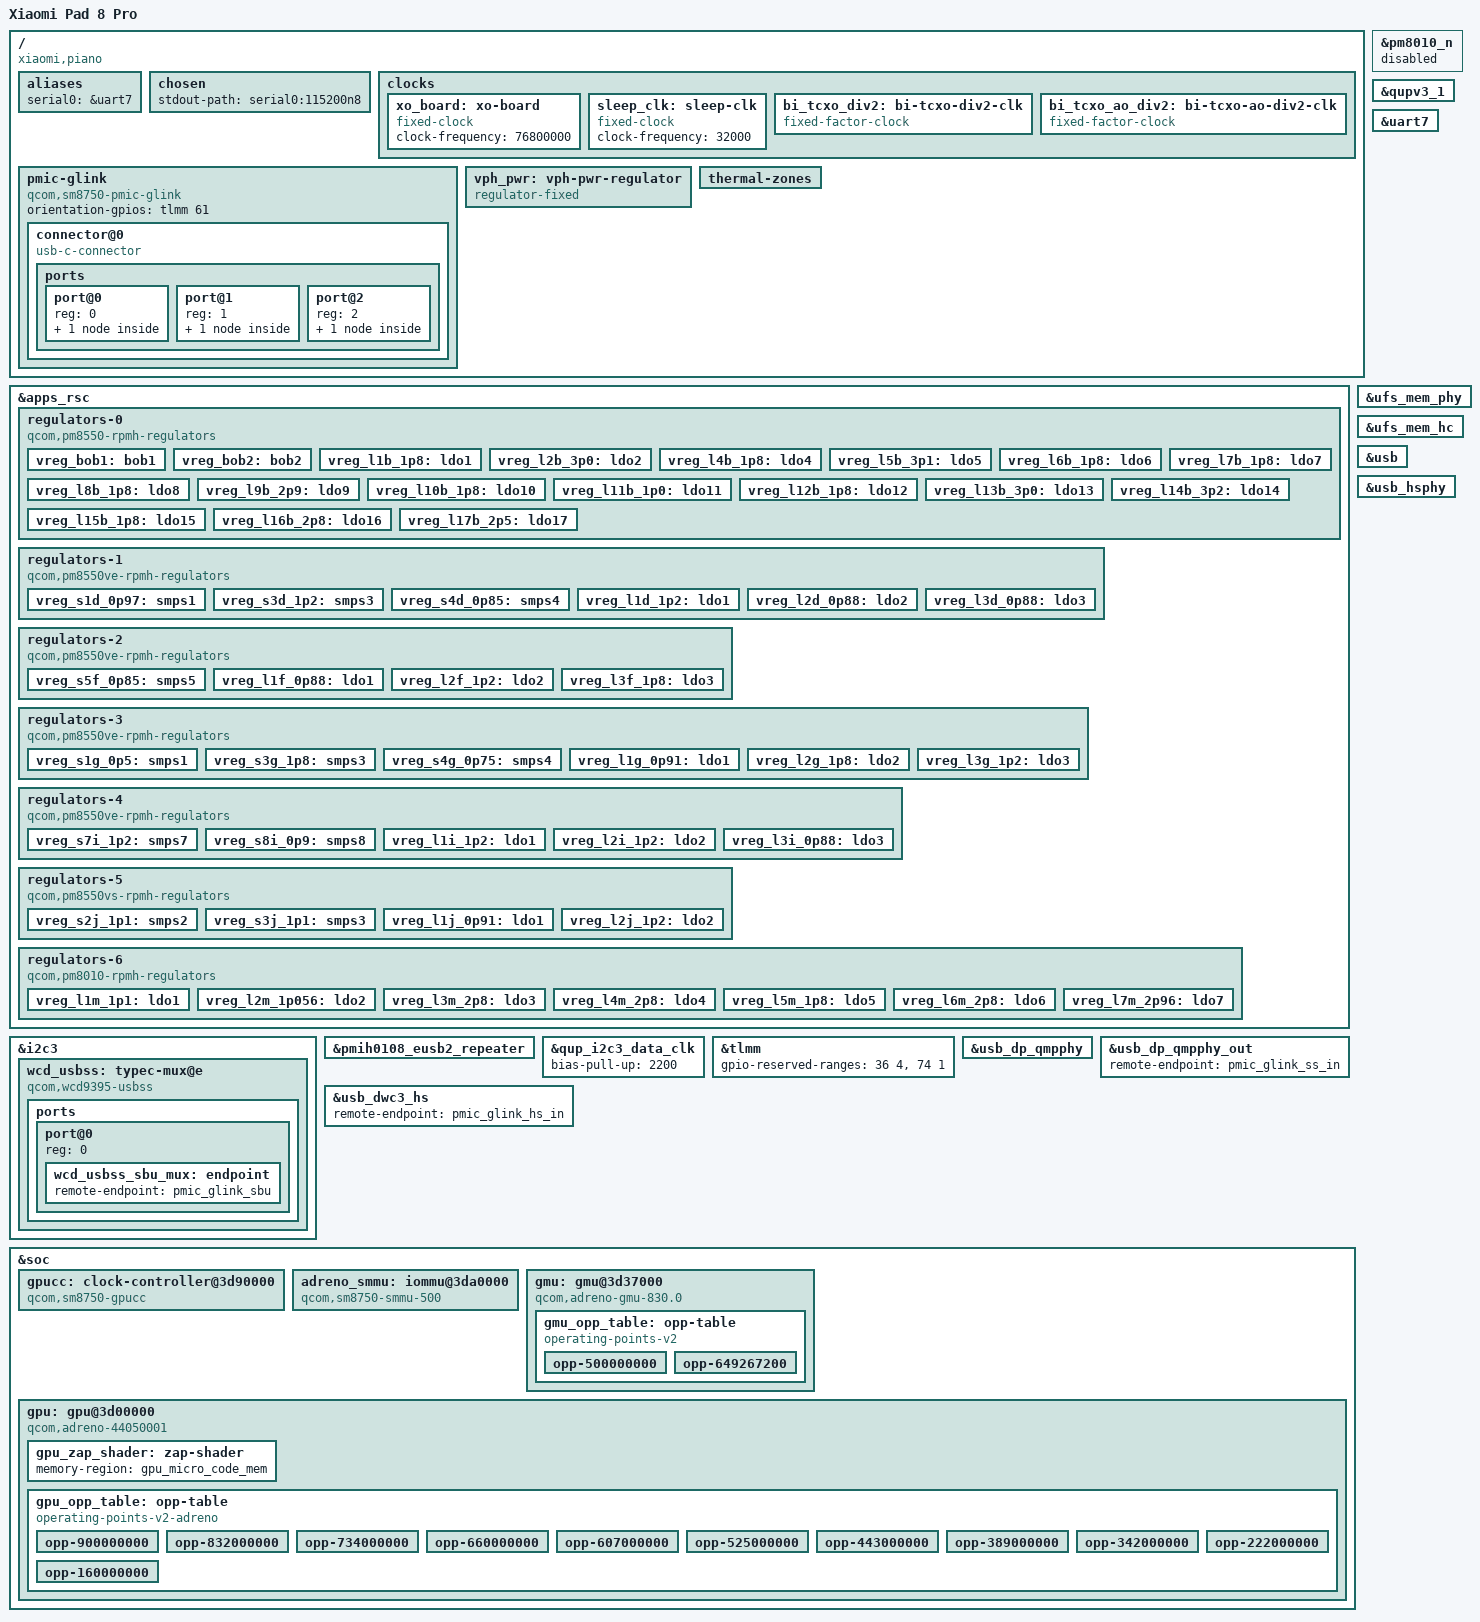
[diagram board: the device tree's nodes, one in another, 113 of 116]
// SPDX-License-Identifier: BSD-3-Clause
/*
 * Copyright (c) 2026, Xiaomi Pad 8 Pro (piano) mainline contributors
 *
 * Xiaomi Pad 8 Pro (codename "piano") bring-up skeleton, structured after
 * the in-tree SM8750 MTP board device tree.
 *
 * v0 scope: first-boot links only — UART7 console, UFS storage, USB DWC3
 * with the eUSB2/QMP PHY stack and the pmic-glink-managed USB-C connector.
 * Display/DSI, audio, WLAN/BT, PCIe, SD, LEDs, touch, keyboard, sensors,
 * GPU and all remoteproc firmware users are intentionally not enabled
 * until they are validated on real hardware.
 *
 * Value provenance markers:
 *   (M) value carried over from the in-tree SM8750 MTP board file
 *   (R) value cross-checked against the Xiaomi downstream kernel
 *       (refer/MiCode_piano/kernel_devicetree)
 * Open questions refer to docs/hardware-facts.md in the umbrella repo.
 */

/dts-v1/;

#include <dt-bindings/gpio/gpio.h>
#include <dt-bindings/regulator/qcom,rpmh-regulator.h>
#include <dt-bindings/clock/qcom,sm8750-gpucc.h>
#include "sm8750.dtsi"
#include "pm8010.dtsi"
#include "pm8550.dtsi"
#define PMK8550VE_SID 8
#include "pm8550ve.dtsi"
#include "pmd8028.dtsi"
#include "pmih0108.dtsi"
#include "pmk8550.dtsi"
#include "pmr735d_a.dtsi"
#include "sm8750-pmics.dtsi"

/ {
	model = "Xiaomi Pad 8 Pro";
	compatible = "xiaomi,piano", "qcom,sm8750";
	chassis-type = "tablet";

	aliases {
		serial0 = &uart7;
	};

	chosen {
		stdout-path = "serial0:115200n8";
	};

	clocks {
		xo_board: xo-board {
			compatible = "fixed-clock";
			clock-frequency = <76800000>;		/* (M) */
			#clock-cells = <0>;
		};

		sleep_clk: sleep-clk {
			compatible = "fixed-clock";
			clock-frequency = <32000>;		/* (M) */
			#clock-cells = <0>;
		};

		bi_tcxo_div2: bi-tcxo-div2-clk {
			compatible = "fixed-factor-clock";
			#clock-cells = <0>;

			clocks = <&rpmhcc RPMH_CXO_CLK>;
			clock-mult = <1>;
			clock-div = <2>;
		};

		bi_tcxo_ao_div2: bi-tcxo-ao-div2-clk {
			compatible = "fixed-factor-clock";
			#clock-cells = <0>;

			clocks = <&rpmhcc RPMH_CXO_CLK_A>;
			clock-mult = <1>;
			clock-div = <2>;
		};
	};

	pmic-glink {
		compatible = "qcom,sm8750-pmic-glink",
			     "qcom,sm8550-pmic-glink",
			     "qcom,pmic-glink";
		#address-cells = <1>;
		#size-cells = <0>;
		orientation-gpios = <&tlmm 61 GPIO_ACTIVE_HIGH>;	/* (M), OQ#11 */

		connector@0 {
			compatible = "usb-c-connector";
			reg = <0>;

			power-role = "dual";
			data-role = "dual";

			ports {
				#address-cells = <1>;
				#size-cells = <0>;

				port@0 {
					reg = <0>;

					pmic_glink_hs_in: endpoint {
						remote-endpoint = <&usb_dwc3_hs>;
					};
				};

				port@1 {
					reg = <1>;

					pmic_glink_ss_in: endpoint {
						remote-endpoint = <&usb_dp_qmpphy_out>;
					};
				};

				port@2 {
					reg = <2>;

					pmic_glink_sbu: endpoint {
						remote-endpoint = <&wcd_usbss_sbu_mux>;
					};
				};
			};
		};
	};

	vph_pwr: vph-pwr-regulator {
		compatible = "regulator-fixed";

		regulator-name = "vph_pwr";
		regulator-min-microvolt = <3700000>;		/* (M) */
		regulator-max-microvolt = <3700000>;		/* (M) */

		regulator-always-on;
		regulator-boot-on;
	};
};

/*
 * Piano hardware omits the second PM8010 die (downstream comment:
 * "Remove PM8010 N for hardware design", refer/MiCode_piano
 * kernel_devicetree/qcom/piano-sm8750.dtsi). (R)
 */
&pm8010_n {
	status = "disabled";
};

/ {
	thermal-zones {
		/delete-node/ pm8010-n-thermal;
	};
};

&apps_rsc {
	/*
	 * Regulator network follows the SM8750 MTP power grid (v8 variant,
	 * same grid downstream sun-mtp-v8). Per-rail assignment for the
	 * piano board is carried from MTP and not yet device-verified. (M)
	 * Open question #10 tracks per-rail validation.
	 */
	regulators-0 {
		compatible = "qcom,pm8550-rpmh-regulators";

		vdd-bob1-supply = <&vph_pwr>;
		vdd-bob2-supply = <&vph_pwr>;
		vdd-l1-l4-l10-supply = <&vreg_s3g_1p8>;
		vdd-l2-l13-l14-supply = <&vreg_bob1>;
		vdd-l3-supply = <&vreg_s7i_1p2>;
		vdd-l5-l16-supply = <&vreg_bob1>;
		vdd-l6-l7-supply = <&vreg_bob1>;
		vdd-l8-l9-supply = <&vreg_bob1>;
		vdd-l11-supply = <&vreg_s7i_1p2>;
		vdd-l12-supply = <&vreg_s3g_1p8>;
		vdd-l15-supply = <&vreg_s3g_1p8>;
		vdd-l17-supply = <&vreg_bob2>;

		qcom,pmic-id = "b";

		vreg_bob1: bob1 {
			regulator-name = "vreg_bob1";
			regulator-min-microvolt = <3008000>;
			regulator-max-microvolt = <4000000>;
			regulator-initial-mode = <RPMH_REGULATOR_MODE_HPM>;
		};

		vreg_bob2: bob2 {
			regulator-name = "vreg_bob2";
			regulator-min-microvolt = <2704000>;
			regulator-max-microvolt = <3008000>;
			regulator-initial-mode = <RPMH_REGULATOR_MODE_HPM>;
		};

		vreg_l1b_1p8: ldo1 {
			regulator-name = "vreg_l1b_1p8";
			regulator-min-microvolt = <1800000>;
			regulator-max-microvolt = <1800000>;
			regulator-initial-mode = <RPMH_REGULATOR_MODE_HPM>;
			regulator-allow-set-load;
			regulator-allowed-modes = <RPMH_REGULATOR_MODE_LPM
						   RPMH_REGULATOR_MODE_HPM>;
		};

		vreg_l2b_3p0: ldo2 {
			regulator-name = "vreg_l2b_3p0";
			regulator-min-microvolt = <3008000>;
			regulator-max-microvolt = <3048000>;
			regulator-initial-mode = <RPMH_REGULATOR_MODE_HPM>;
			regulator-allow-set-load;
			regulator-allowed-modes = <RPMH_REGULATOR_MODE_LPM
						   RPMH_REGULATOR_MODE_HPM>;
		};

		vreg_l4b_1p8: ldo4 {
			regulator-name = "vreg_l4b_1p8";
			regulator-min-microvolt = <1800000>;
			regulator-max-microvolt = <1800000>;
			regulator-initial-mode = <RPMH_REGULATOR_MODE_HPM>;
			regulator-allow-set-load;
			regulator-allowed-modes = <RPMH_REGULATOR_MODE_LPM
						   RPMH_REGULATOR_MODE_HPM>;
		};

		vreg_l5b_3p1: ldo5 {
			regulator-name = "vreg_l5b_3p1";
			regulator-min-microvolt = <3100000>;
			regulator-max-microvolt = <3148000>;
			regulator-initial-mode = <RPMH_REGULATOR_MODE_HPM>;
			regulator-allow-set-load;
			regulator-allowed-modes = <RPMH_REGULATOR_MODE_LPM
						   RPMH_REGULATOR_MODE_HPM>;
		};

		vreg_l6b_1p8: ldo6 {
			regulator-name = "vreg_l6b_1p8";
			regulator-min-microvolt = <1800000>;
			regulator-max-microvolt = <3008000>;
			regulator-initial-mode = <RPMH_REGULATOR_MODE_HPM>;
			regulator-allow-set-load;
			regulator-allowed-modes = <RPMH_REGULATOR_MODE_LPM
						   RPMH_REGULATOR_MODE_HPM>;
		};

		vreg_l7b_1p8: ldo7 {
			regulator-name = "vreg_l7b_1p8";
			regulator-min-microvolt = <1800000>;
			regulator-max-microvolt = <3008000>;
			regulator-initial-mode = <RPMH_REGULATOR_MODE_HPM>;
			regulator-allow-set-load;
			regulator-allowed-modes = <RPMH_REGULATOR_MODE_LPM
						   RPMH_REGULATOR_MODE_HPM>;
		};

		vreg_l8b_1p8: ldo8 {
			regulator-name = "vreg_l8b_1p8";
			regulator-min-microvolt = <1800000>;
			regulator-max-microvolt = <3008000>;
			regulator-initial-mode = <RPMH_REGULATOR_MODE_HPM>;
			regulator-allow-set-load;
			regulator-allowed-modes = <RPMH_REGULATOR_MODE_LPM
						   RPMH_REGULATOR_MODE_HPM>;
		};

		vreg_l9b_2p9: ldo9 {
			regulator-name = "vreg_l9b_2p9";
			regulator-min-microvolt = <2960000>;
			regulator-max-microvolt = <3008000>;
			regulator-initial-mode = <RPMH_REGULATOR_MODE_HPM>;
			regulator-allow-set-load;
			regulator-allowed-modes = <RPMH_REGULATOR_MODE_LPM
						   RPMH_REGULATOR_MODE_HPM>;
		};

		vreg_l10b_1p8: ldo10 {
			regulator-name = "vreg_l10b_1p8";
			regulator-min-microvolt = <1800000>;
			regulator-max-microvolt = <1800000>;
			regulator-initial-mode = <RPMH_REGULATOR_MODE_HPM>;
			regulator-allow-set-load;
			regulator-allowed-modes = <RPMH_REGULATOR_MODE_LPM
						   RPMH_REGULATOR_MODE_HPM>;
		};

		vreg_l11b_1p0: ldo11 {
			regulator-name = "vreg_l11b_1p0";
			regulator-min-microvolt = <1064000>;
			regulator-max-microvolt = <1292000>;
			regulator-initial-mode = <RPMH_REGULATOR_MODE_HPM>;
			regulator-allow-set-load;
			regulator-allowed-modes = <RPMH_REGULATOR_MODE_LPM
						   RPMH_REGULATOR_MODE_HPM>;
		};

		vreg_l12b_1p8: ldo12 {
			regulator-name = "vreg_l12b_1p8";
			regulator-min-microvolt = <1200000>;
			regulator-max-microvolt = <1800000>;
			regulator-initial-mode = <RPMH_REGULATOR_MODE_HPM>;
			regulator-allow-set-load;
			regulator-allowed-modes = <RPMH_REGULATOR_MODE_LPM
						   RPMH_REGULATOR_MODE_HPM>;
		};

		vreg_l13b_3p0: ldo13 {
			regulator-name = "vreg_l13b_3p0";
			regulator-min-microvolt = <3000000>;
			regulator-max-microvolt = <3000000>;
			regulator-initial-mode = <RPMH_REGULATOR_MODE_HPM>;
			regulator-allow-set-load;
			regulator-allowed-modes = <RPMH_REGULATOR_MODE_LPM
						   RPMH_REGULATOR_MODE_HPM>;
		};

		vreg_l14b_3p2: ldo14 {
			regulator-name = "vreg_l14b_3p2";
			regulator-min-microvolt = <3200000>;
			regulator-max-microvolt = <3200000>;
			regulator-initial-mode = <RPMH_REGULATOR_MODE_HPM>;
			regulator-allow-set-load;
			regulator-allowed-modes = <RPMH_REGULATOR_MODE_LPM
						   RPMH_REGULATOR_MODE_HPM>;
		};

		vreg_l15b_1p8: ldo15 {
			regulator-name = "vreg_l15b_1p8";
			regulator-min-microvolt = <1800000>;
			regulator-max-microvolt = <1800000>;
			regulator-initial-mode = <RPMH_REGULATOR_MODE_HPM>;
			regulator-allow-set-load;
			regulator-allowed-modes = <RPMH_REGULATOR_MODE_LPM
						   RPMH_REGULATOR_MODE_HPM>;
		};

		vreg_l16b_2p8: ldo16 {
			regulator-name = "vreg_l16b_2p8";
			regulator-min-microvolt = <2800000>;
			regulator-max-microvolt = <2800000>;
			regulator-initial-mode = <RPMH_REGULATOR_MODE_HPM>;
			regulator-allow-set-load;
			regulator-allowed-modes = <RPMH_REGULATOR_MODE_LPM
						   RPMH_REGULATOR_MODE_HPM>;
		};

		vreg_l17b_2p5: ldo17 {
			regulator-name = "vreg_l17b_2p5";
			regulator-min-microvolt = <2504000>;
			regulator-max-microvolt = <2504000>;
			regulator-initial-mode = <RPMH_REGULATOR_MODE_HPM>;
			regulator-allow-set-load;
			regulator-allowed-modes = <RPMH_REGULATOR_MODE_LPM
						   RPMH_REGULATOR_MODE_HPM>;
		};
	};

	regulators-1 {
		compatible = "qcom,pm8550ve-rpmh-regulators";

		vdd-l1-supply = <&vreg_s7i_1p2>;
		vdd-l2-supply = <&vreg_s1d_0p97>;
		vdd-l3-supply = <&vreg_s1d_0p97>;
		vdd-s1-supply = <&vph_pwr>;
		vdd-s3-supply = <&vph_pwr>;
		vdd-s4-supply = <&vph_pwr>;

		qcom,pmic-id = "d";

		vreg_s1d_0p97: smps1 {
			regulator-name = "vreg_s1d_0p97";
			regulator-min-microvolt = <880000>;
			regulator-max-microvolt = <1100000>;
			regulator-initial-mode = <RPMH_REGULATOR_MODE_HPM>;
		};

		vreg_s3d_1p2: smps3 {
			regulator-name = "vreg_s3d_1p2";
			regulator-min-microvolt = <1200000>;
			regulator-max-microvolt = <1300000>;
			regulator-initial-mode = <RPMH_REGULATOR_MODE_HPM>;
		};

		vreg_s4d_0p85: smps4 {
			regulator-name = "vreg_s4d_0p85";
			regulator-min-microvolt = <852000>;
			regulator-max-microvolt = <1036000>;
			regulator-initial-mode = <RPMH_REGULATOR_MODE_HPM>;
		};

		vreg_l1d_1p2: ldo1 {
			regulator-name = "vreg_l1d_1p2";
			regulator-min-microvolt = <1200000>;
			regulator-max-microvolt = <1200000>;
			regulator-initial-mode = <RPMH_REGULATOR_MODE_HPM>;
			regulator-allow-set-load;
			regulator-allowed-modes = <RPMH_REGULATOR_MODE_LPM
						   RPMH_REGULATOR_MODE_HPM>;
		};

		vreg_l2d_0p88: ldo2 {
			regulator-name = "vreg_l2d_0p88";
			regulator-min-microvolt = <880000>;
			regulator-max-microvolt = <912000>;
			regulator-initial-mode = <RPMH_REGULATOR_MODE_HPM>;
			regulator-allow-set-load;
			regulator-allowed-modes = <RPMH_REGULATOR_MODE_LPM
						   RPMH_REGULATOR_MODE_HPM>;
		};

		vreg_l3d_0p88: ldo3 {
			regulator-name = "vreg_l3d_0p88";
			regulator-min-microvolt = <880000>;
			regulator-max-microvolt = <920000>;
			regulator-initial-mode = <RPMH_REGULATOR_MODE_HPM>;
			regulator-allow-set-load;
			regulator-allowed-modes = <RPMH_REGULATOR_MODE_LPM
						   RPMH_REGULATOR_MODE_HPM>;
		};
	};

	regulators-2 {
		compatible = "qcom,pm8550ve-rpmh-regulators";

		vdd-l1-supply = <&vreg_s1d_0p97>;
		vdd-l2-supply = <&vreg_s7i_1p2>;
		vdd-l3-supply = <&vreg_s3g_1p8>;
		vdd-s5-supply = <&vph_pwr>;

		qcom,pmic-id = "f";

		vreg_s5f_0p85: smps5 {
			regulator-name = "vreg_s5f_0p85";
			regulator-min-microvolt = <852000>;
			regulator-max-microvolt = <1000000>;
			regulator-initial-mode = <RPMH_REGULATOR_MODE_HPM>;
		};

		vreg_l1f_0p88: ldo1 {
			regulator-name = "vreg_l1f_0p88";
			regulator-min-microvolt = <880000>;
			regulator-max-microvolt = <920000>;
			regulator-initial-mode = <RPMH_REGULATOR_MODE_HPM>;
			regulator-allow-set-load;
			regulator-allowed-modes = <RPMH_REGULATOR_MODE_LPM
						   RPMH_REGULATOR_MODE_HPM>;
		};

		vreg_l2f_1p2: ldo2 {
			regulator-name = "vreg_l2f_1p2";
			regulator-min-microvolt = <1200000>;
			regulator-max-microvolt = <1200000>;
			regulator-initial-mode = <RPMH_REGULATOR_MODE_HPM>;
			regulator-allow-set-load;
			regulator-allowed-modes = <RPMH_REGULATOR_MODE_LPM
						   RPMH_REGULATOR_MODE_HPM>;
		};

		vreg_l3f_1p8: ldo3 {
			regulator-name = "vreg_l3f_1p8";
			regulator-min-microvolt = <1800000>;
			regulator-max-microvolt = <1800000>;
			regulator-initial-mode = <RPMH_REGULATOR_MODE_HPM>;
			regulator-allow-set-load;
			regulator-allowed-modes = <RPMH_REGULATOR_MODE_LPM
						   RPMH_REGULATOR_MODE_HPM>;
		};
	};

	regulators-3 {
		compatible = "qcom,pm8550ve-rpmh-regulators";

		vdd-l1-supply = <&vreg_s1d_0p97>;
		vdd-l2-supply = <&vreg_s3g_1p8>;
		vdd-l3-supply = <&vreg_s7i_1p2>;
		vdd-s1-supply = <&vph_pwr>;
		vdd-s3-supply = <&vph_pwr>;

		qcom,pmic-id = "g";

		vreg_s1g_0p5: smps1 {
			regulator-name = "vreg_s1g_0p5";
			regulator-min-microvolt = <300000>;
			regulator-max-microvolt = <700000>;
			regulator-initial-mode = <RPMH_REGULATOR_MODE_HPM>;
		};

		vreg_s3g_1p8: smps3 {
			regulator-name = "vreg_s3g_1p8";
			regulator-min-microvolt = <1856000>;
			regulator-max-microvolt = <2000000>;
			regulator-initial-mode = <RPMH_REGULATOR_MODE_LPM>;
			regulator-allow-set-load;
			regulator-allowed-modes = <RPMH_REGULATOR_MODE_LPM
						   RPMH_REGULATOR_MODE_HPM>;
		};

		vreg_s4g_0p75: smps4 {
			regulator-name = "vreg_s4g_0p75";
			regulator-min-microvolt = <300000>;
			regulator-max-microvolt = <900000>;
			regulator-initial-mode = <RPMH_REGULATOR_MODE_HPM>;
		};

		vreg_l1g_0p91: ldo1 {
			regulator-name = "vreg_l1g_0p91";
			regulator-min-microvolt = <912000>;
			regulator-max-microvolt = <936000>;
			regulator-initial-mode = <RPMH_REGULATOR_MODE_HPM>;
			regulator-allow-set-load;
			regulator-allowed-modes = <RPMH_REGULATOR_MODE_LPM
						   RPMH_REGULATOR_MODE_HPM>;
		};

		vreg_l2g_1p8: ldo2 {
			regulator-name = "vreg_l2g_1p8";
			regulator-min-microvolt = <1200000>;
			regulator-max-microvolt = <1860000>;
			regulator-initial-mode = <RPMH_REGULATOR_MODE_HPM>;
			regulator-allow-set-load;
			regulator-allowed-modes = <RPMH_REGULATOR_MODE_LPM
						   RPMH_REGULATOR_MODE_HPM>;
		};

		vreg_l3g_1p2: ldo3 {
			regulator-name = "vreg_l3g_1p2";
			regulator-min-microvolt = <1200000>;
			regulator-max-microvolt = <1256000>;
			regulator-initial-mode = <RPMH_REGULATOR_MODE_HPM>;
			regulator-allow-set-load;
			regulator-allowed-modes = <RPMH_REGULATOR_MODE_LPM
						   RPMH_REGULATOR_MODE_HPM>;
		};
	};

	regulators-4 {
		compatible = "qcom,pm8550ve-rpmh-regulators";

		vdd-l1-supply = <&vreg_s7i_1p2>;
		vdd-l2-supply = <&vreg_s7i_1p2>;
		vdd-l3-supply = <&vreg_s1d_0p97>;
		vdd-s7-supply = <&vph_pwr>;
		vdd-s8-supply = <&vph_pwr>;

		qcom,pmic-id = "i";

		vreg_s7i_1p2: smps7 {
			regulator-name = "vreg_s7i_1p2";
			regulator-min-microvolt = <1224000>;
			regulator-max-microvolt = <1340000>;
			regulator-initial-mode = <RPMH_REGULATOR_MODE_HPM>;
		};

		vreg_s8i_0p9: smps8 {
			regulator-name = "vreg_s8i_0p9";
			regulator-min-microvolt = <900000>;
			regulator-max-microvolt = <972000>;
			regulator-initial-mode = <RPMH_REGULATOR_MODE_HPM>;
		};

		vreg_l1i_1p2: ldo1 {
			regulator-name = "vreg_l1i_1p2";
			regulator-min-microvolt = <1200000>;
			regulator-max-microvolt = <1200000>;
			regulator-initial-mode = <RPMH_REGULATOR_MODE_HPM>;
			regulator-allow-set-load;
			regulator-allowed-modes = <RPMH_REGULATOR_MODE_LPM
						   RPMH_REGULATOR_MODE_HPM>;
		};

		vreg_l2i_1p2: ldo2 {
			regulator-name = "vreg_l2i_1p2";
			regulator-min-microvolt = <1200000>;
			regulator-max-microvolt = <1200000>;
			regulator-initial-mode = <RPMH_REGULATOR_MODE_HPM>;
			regulator-allow-set-load;
			regulator-allowed-modes = <RPMH_REGULATOR_MODE_LPM
						   RPMH_REGULATOR_MODE_HPM>;
		};

		vreg_l3i_0p88: ldo3 {
			regulator-name = "vreg_l3i_0p88";
			regulator-min-microvolt = <880000>;
			regulator-max-microvolt = <912000>;
			regulator-initial-mode = <RPMH_REGULATOR_MODE_HPM>;
			regulator-allow-set-load;
			regulator-allowed-modes = <RPMH_REGULATOR_MODE_LPM
						   RPMH_REGULATOR_MODE_HPM>;
		};
	};

	regulators-5 {
		compatible = "qcom,pm8550vs-rpmh-regulators";

		vdd-l1-supply = <&vreg_s1d_0p97>;
		vdd-l2-supply = <&vreg_s7i_1p2>;
		vdd-s2-supply = <&vph_pwr>;
		vdd-s3-supply = <&vph_pwr>;
		vdd-s4-supply = <&vph_pwr>;

		qcom,pmic-id = "j";

		vreg_s2j_1p1: smps2 {
			regulator-name = "vreg_s2j_1p1";
			regulator-min-microvolt = <1000000>;
			regulator-max-microvolt = <1100000>;
			regulator-initial-mode = <RPMH_REGULATOR_MODE_HPM>;
		};

		vreg_s3j_1p1: smps3 {
			regulator-name = "vreg_s3j_1p1";
			regulator-min-microvolt = <1000000>;
			regulator-max-microvolt = <1100000>;
			regulator-initial-mode = <RPMH_REGULATOR_MODE_HPM>;
		};

		vreg_l1j_0p91: ldo1 {
			regulator-name = "vreg_l1j_0p91";
			regulator-min-microvolt = <880000>;
			regulator-max-microvolt = <920000>;
			regulator-initial-mode = <RPMH_REGULATOR_MODE_HPM>;
			regulator-allow-set-load;
			regulator-allowed-modes = <RPMH_REGULATOR_MODE_LPM
						   RPMH_REGULATOR_MODE_HPM>;
		};

		vreg_l2j_1p2: ldo2 {
			regulator-name = "vreg_l2j_1p2";
			regulator-min-microvolt = <1200000>;
			regulator-max-microvolt = <1200000>;
			regulator-initial-mode = <RPMH_REGULATOR_MODE_HPM>;
			regulator-allow-set-load;
			regulator-allowed-modes = <RPMH_REGULATOR_MODE_LPM
						   RPMH_REGULATOR_MODE_HPM>;
		};
	};

	regulators-6 {
		compatible = "qcom,pm8010-rpmh-regulators";
		qcom,pmic-id = "m";

		vdd-l1-l2-supply = <&vreg_s7i_1p2>;
		vdd-l3-l4-supply = <&vreg_bob2>;
		vdd-l5-supply = <&vreg_s3g_1p8>;
		vdd-l6-supply = <&vreg_bob1>;
		vdd-l7-supply = <&vreg_bob1>;

		vreg_l1m_1p1: ldo1 {
			regulator-name = "vreg_l1m_1p1";
			regulator-min-microvolt = <1104000>;
			regulator-max-microvolt = <1104000>;
			regulator-initial-mode = <RPMH_REGULATOR_MODE_HPM>;
			regulator-allow-set-load;
			regulator-allowed-modes = <RPMH_REGULATOR_MODE_LPM
						   RPMH_REGULATOR_MODE_HPM>;
		};

		vreg_l2m_1p056: ldo2 {
			regulator-name = "vreg_l2m_1p056";
			regulator-min-microvolt = <1056000>;
			regulator-max-microvolt = <1056000>;
			regulator-initial-mode = <RPMH_REGULATOR_MODE_HPM>;
			regulator-allow-set-load;
			regulator-allowed-modes = <RPMH_REGULATOR_MODE_LPM
						   RPMH_REGULATOR_MODE_HPM>;
		};

		vreg_l3m_2p8: ldo3 {
			regulator-name = "vreg_l3m_2p8";
			regulator-min-microvolt = <2800000>;
			regulator-max-microvolt = <2800000>;
			regulator-initial-mode = <RPMH_REGULATOR_MODE_HPM>;
		};

		vreg_l4m_2p8: ldo4 {
			regulator-name = "vreg_l4m_2p8";
			regulator-min-microvolt = <2800000>;
			regulator-max-microvolt = <2800000>;
			regulator-initial-mode = <RPMH_REGULATOR_MODE_HPM>;
		};

		vreg_l5m_1p8: ldo5 {
			regulator-name = "vreg_l5m_1p8";
			regulator-min-microvolt = <1800000>;
			regulator-max-microvolt = <1800000>;
			regulator-initial-mode = <RPMH_REGULATOR_MODE_HPM>;
		};

		vreg_l6m_2p8: ldo6 {
			regulator-name = "vreg_l6m_2p8";
			regulator-min-microvolt = <2800000>;
			regulator-max-microvolt = <2800000>;
			regulator-initial-mode = <RPMH_REGULATOR_MODE_HPM>;
		};

		vreg_l7m_2p96: ldo7 {
			regulator-name = "vreg_l7m_2p96";
			regulator-min-microvolt = <2960000>;
			regulator-max-microvolt = <2960000>;
			regulator-initial-mode = <RPMH_REGULATOR_MODE_HPM>;
		};
	};

	/* No regulators-7 (pmic-id "n"): piano omits the second PM8010 die. (R) */
};

&i2c3 {
	status = "okay";

	/*
	 * WCD9395 USBSS SBU/orientation switch for the USB-C connector.
	 * Presence on piano confirmed downstream (sun.dtsi wcd939x_i2c@e,
	 * referenced by &usb0 qcom,wcd_usbss). (R)
	 */
	wcd_usbss: typec-mux@e {
		compatible = "qcom,wcd9395-usbss", "qcom,wcd9390-usbss";
		reg = <0xe>;				/* (R) */

		vdd-supply = <&vreg_l15b_1p8>;		/* (M) */
		reset-gpios = <&tlmm 152 GPIO_ACTIVE_HIGH>;	/* (M), OQ#11 */

		mode-switch;
		orientation-switch;

		ports {
			#address-cells = <1>;
			#size-cells = <0>;

			port@0 {
				reg = <0>;

				wcd_usbss_sbu_mux: endpoint {
					remote-endpoint = <&pmic_glink_sbu>;
				};
			};
		};
	};
};

&pmih0108_eusb2_repeater {
	qcom,tune-usb2-preem = /bits/ 8 <0x3>;		/* (M), OQ#12 */
	qcom,tune-usb2-amplitude = /bits/ 8 <0xa>;	/* (M), OQ#12 */
	qcom,squelch-detector-bp = <(-2000)>;		/* (M), OQ#12 */

	vdd18-supply = <&vreg_l15b_1p8>;			/* (M) */
	vdd3-supply = <&vreg_l5b_3p1>;				/* (M) */

	status = "okay";
};

&qup_i2c3_data_clk {
	/* Use internal I2C pull-up */
	bias-pull-up = <2200>;
};

&qupv3_1 {
	status = "okay";
};

&tlmm {
	gpio-reserved-ranges = <36 4>, <74 1>;		/* (M), OQ#13 */
};

&uart7 {
	status = "okay";
};

&ufs_mem_phy {
	vdda-phy-supply = <&vreg_l1j_0p91>;		/* (M), OQ#14 */
	vdda-pll-supply = <&vreg_l3g_1p2>;		/* (M), OQ#14 */

	status = "okay";
};

&ufs_mem_hc {
	reset-gpios = <&tlmm 215 GPIO_ACTIVE_LOW>;	/* (M), OQ#14 */

	vcc-supply = <&vreg_l17b_2p5>;			/* (M), OQ#14 */
	vcc-max-microamp = <1300000>;
	vccq-supply = <&vreg_l1d_1p2>;			/* (M), OQ#14 */
	vccq-max-microamp = <1200000>;

	status = "okay";
};

&usb {
	status = "okay";
};

&usb_dp_qmpphy {
	vdda-phy-supply = <&vreg_l2d_0p88>;		/* (M), OQ#14 */
	vdda-pll-supply = <&vreg_l3g_1p2>;		/* (M), OQ#14 */

	status = "okay";
};

&usb_dp_qmpphy_out {
	remote-endpoint = <&pmic_glink_ss_in>;
};

&usb_dwc3_hs {
	remote-endpoint = <&pmic_glink_hs_in>;
};

&usb_hsphy {
	vdd-supply = <&vreg_l2d_0p88>;			/* (M), OQ#14 */
	vdda12-supply = <&vreg_l3g_1p2>;		/* (M), OQ#14 */

	phys = <&pmih0108_eusb2_repeater>;

	status = "okay";
};

/*
 * Adreno 830 (A8x family) GPU stack. EXPERIMENTAL bp/gpu-v1 branch:
 * do not merge without real-device validation.
 *
 * Register map, IRQs (GPU 300, GMU hfi/gmu 304/305), SMMU @0x3da0000
 * and zap region provenance: stock vbdtb-00.dts (local/dtb-downstream),
 * re-shaped onto upstream drm/msm DT conventions (gpu.yaml/gmu.yaml).
 *
 * Known gap: stock SM8750 controls the GX domain through a dedicated
 * "qcom,sun-gx_clkctl" block (0x3d68024) with vdd_gx, which has no
 * upstream driver; drivers/clk/qcom/gpucc-sm8750.c exposes only
 * GPU_CC_CX_GDSC. The a8xx GMU driver treats the gx power domain as
 * optional (recovery-only), so this node votes cx only and the local
 * gmu.yaml copy was relaxed accordingly (see commit message).
 */
&soc {
	gpucc: clock-controller@3d90000 {
		compatible = "qcom,sm8750-gpucc";
		reg = <0x0 0x03d90000 0x0 0x9800>;		/* (R) */

		clocks = <&bi_tcxo_div2>,
			 <&gcc GCC_GPU_GPLL0_CLK_SRC>,
			 <&gcc GCC_GPU_GPLL0_DIV_CLK_SRC>;

		power-domains = <&rpmhpd RPMHPD_MX>,
				<&rpmhpd RPMHPD_CX>;
		required-opps = <&rpmhpd_opp_low_svs>,
				<&rpmhpd_opp_low_svs>;

		#clock-cells = <1>;
		#reset-cells = <1>;
		#power-domain-cells = <1>;
	};

	adreno_smmu: iommu@3da0000 {
		compatible = "qcom,sm8750-smmu-500", "qcom,adreno-smmu",
			     "qcom,smmu-500", "arm,mmu-500";
		reg = <0x0 0x03da0000 0x0 0x40000>;		/* (R) */
		#iommu-cells = <2>;
		#global-interrupts = <1>;
		interrupts = <GIC_SPI 674 IRQ_TYPE_LEVEL_HIGH>,		/* (R) */
			     <GIC_SPI 678 IRQ_TYPE_LEVEL_HIGH>,
			     <GIC_SPI 679 IRQ_TYPE_LEVEL_HIGH>,
			     <GIC_SPI 680 IRQ_TYPE_LEVEL_HIGH>,
			     <GIC_SPI 681 IRQ_TYPE_LEVEL_HIGH>,
			     <GIC_SPI 682 IRQ_TYPE_LEVEL_HIGH>,
			     <GIC_SPI 683 IRQ_TYPE_LEVEL_HIGH>,
			     <GIC_SPI 684 IRQ_TYPE_LEVEL_HIGH>,
			     <GIC_SPI 685 IRQ_TYPE_LEVEL_HIGH>,
			     <GIC_SPI 686 IRQ_TYPE_LEVEL_HIGH>,
			     <GIC_SPI 687 IRQ_TYPE_LEVEL_HIGH>,
			     <GIC_SPI 688 IRQ_TYPE_LEVEL_HIGH>,
			     <GIC_SPI 422 IRQ_TYPE_LEVEL_HIGH>,
			     <GIC_SPI 476 IRQ_TYPE_LEVEL_HIGH>,
			     <GIC_SPI 574 IRQ_TYPE_LEVEL_HIGH>,
			     <GIC_SPI 575 IRQ_TYPE_LEVEL_HIGH>,
			     <GIC_SPI 576 IRQ_TYPE_LEVEL_HIGH>,
			     <GIC_SPI 577 IRQ_TYPE_LEVEL_HIGH>,
			     <GIC_SPI 660 IRQ_TYPE_LEVEL_HIGH>,
			     <GIC_SPI 662 IRQ_TYPE_LEVEL_HIGH>,
			     <GIC_SPI 665 IRQ_TYPE_LEVEL_HIGH>,
			     <GIC_SPI 666 IRQ_TYPE_LEVEL_HIGH>,
			     <GIC_SPI 667 IRQ_TYPE_LEVEL_HIGH>,
			     <GIC_SPI 669 IRQ_TYPE_LEVEL_HIGH>,
			     <GIC_SPI 670 IRQ_TYPE_LEVEL_HIGH>,
			     <GIC_SPI 700 IRQ_TYPE_LEVEL_HIGH>;

		clocks = <&gpucc GPU_CC_HLOS1_VOTE_GPU_SMMU_CLK>;
		clock-names = "hlos";

		power-domains = <&gpucc GPU_CC_CX_GDSC>;
		dma-coherent;
	};

	gmu: gmu@3d37000 {
		compatible = "qcom,adreno-gmu-830.0", "qcom,adreno-gmu";
		reg = <0x0 0x03d37000 0x0 0x68000>;		/* (R) */
		reg-names = "gmu";

		interrupts = <GIC_SPI 304 IRQ_TYPE_LEVEL_HIGH>,		/* (R) */
			     <GIC_SPI 305 IRQ_TYPE_LEVEL_HIGH>;
		interrupt-names = "hfi", "gmu";

		clocks = <&gpucc GPU_CC_AHB_CLK>,
			 <&gpucc GPU_CC_CX_GMU_CLK>,
			 <&gpucc GPU_CC_CXO_CLK>,
			 <&gcc GCC_DDRSS_GPU_AXI_CLK>,
			 <&gcc GCC_GPU_GEMNOC_GFX_CLK>,
			 <&gpucc GPU_CC_HUB_CX_INT_CLK>;
		clock-names = "ahb", "gmu", "cxo", "axi", "memnoc", "hub";

		power-domains = <&gpucc GPU_CC_CX_GDSC>;
		power-domain-names = "cx";

		iommus = <&adreno_smmu 5 0x0>;
		qcom,qmp = <&aoss_qmp>;

		operating-points-v2 = <&gmu_opp_table>;

		gmu_opp_table: opp-table {
			compatible = "operating-points-v2";

			opp-500000000 {
				opp-hz = /bits/ 64 <500000000>;		/* (R) */
				opp-level = <RPMH_REGULATOR_LEVEL_LOW_SVS>;
			};

			opp-649267200 {
				opp-hz = /bits/ 64 <649267200>;		/* (R) */
				opp-level = <RPMH_REGULATOR_LEVEL_SVS>;
			};
		};
	};

	gpu: gpu@3d00000 {
		compatible = "qcom,adreno-44050001", "qcom,adreno";
		reg = <0x0 0x03d00000 0x0 0x40000>,		/* (R) */
		      <0x0 0x03d9e000 0x0 0x2000>,
		      <0x0 0x03d61000 0x0 0x3000>;
		reg-names = "kgsl_3d0_reg_memory", "cx_mem", "cx_dbgc";

		interrupts = <GIC_SPI 300 IRQ_TYPE_LEVEL_HIGH>;		/* (R) */

		iommus = <&adreno_smmu 0 0x0>,
			 <&adreno_smmu 1 0x0>;

		operating-points-v2 = <&gpu_opp_table>;

		qcom,gmu = <&gmu>;
		#cooling-cells = <2>;

		interconnects = <&gem_noc MASTER_GFX3D QCOM_ICC_TAG_ALWAYS
				 &mc_virt SLAVE_EBI1 QCOM_ICC_TAG_ALWAYS>;
		interconnect-names = "gfx-mem";

		status = "okay";

		gpu_zap_shader: zap-shader {
			memory-region = <&gpu_micro_code_mem>;
		};

		/*
		 * Provisional OPP table (speed-bin 0xbe, the lowest fuse
		 * bin, 11 levels 160-900 MHz from stock qcom,gpu-pwrlevels;
		 * frequencies and DDR peaks are stock values, the
		 * opp-level ladder is mapped positionally after sm8650 and
		 * MUST be validated on a real device before any merge.
		 */
		gpu_opp_table: opp-table {
			compatible = "operating-points-v2-adreno",
				     "operating-points-v2";

			opp-900000000 {
				opp-hz = /bits/ 64 <900000000>;
				opp-level = <RPMH_REGULATOR_LEVEL_NOM_L1>;
				opp-peak-kBps = <18597656>;
			};

			opp-832000000 {
				opp-hz = /bits/ 64 <832000000>;
				opp-level = <RPMH_REGULATOR_LEVEL_NOM>;
				opp-peak-kBps = <16500000>;
			};

			opp-734000000 {
				opp-hz = /bits/ 64 <734000000>;
				opp-level = <RPMH_REGULATOR_LEVEL_SVS_L2>;
				opp-peak-kBps = <14398437>;
			};

			opp-660000000 {
				opp-hz = /bits/ 64 <660000000>;
				opp-level = <RPMH_REGULATOR_LEVEL_SVS_L1>;
				opp-peak-kBps = <12449218>;
			};

			opp-607000000 {
				opp-hz = /bits/ 64 <607000000>;
				opp-level = <RPMH_REGULATOR_LEVEL_SVS_L0>;
				opp-peak-kBps = <10687500>;
			};

			opp-525000000 {
				opp-hz = /bits/ 64 <525000000>;
				opp-level = <RPMH_REGULATOR_LEVEL_SVS>;
				opp-peak-kBps = <8171875>;
			};

			opp-443000000 {
				opp-hz = /bits/ 64 <443000000>;
				opp-level = <RPMH_REGULATOR_LEVEL_LOW_SVS_L1>;
				opp-peak-kBps = <6671875>;
			};

			opp-389000000 {
				opp-hz = /bits/ 64 <389000000>;
				opp-level = <RPMH_REGULATOR_LEVEL_LOW_SVS>;
				opp-peak-kBps = <6074218>;
			};

			opp-342000000 {
				opp-hz = /bits/ 64 <342000000>;
				opp-level = <RPMH_REGULATOR_LEVEL_LOW_SVS_D0>;
				opp-peak-kBps = <5285156>;
			};

			opp-222000000 {
				opp-hz = /bits/ 64 <222000000>;
				opp-level = <RPMH_REGULATOR_LEVEL_LOW_SVS_D1>;
				opp-peak-kBps = <2136718>;
			};

			opp-160000000 {
				opp-hz = /bits/ 64 <160000000>;
				opp-level = <RPMH_REGULATOR_LEVEL_LOW_SVS_D2>;
				opp-peak-kBps = <781250>;
			};
		};
	};
};
